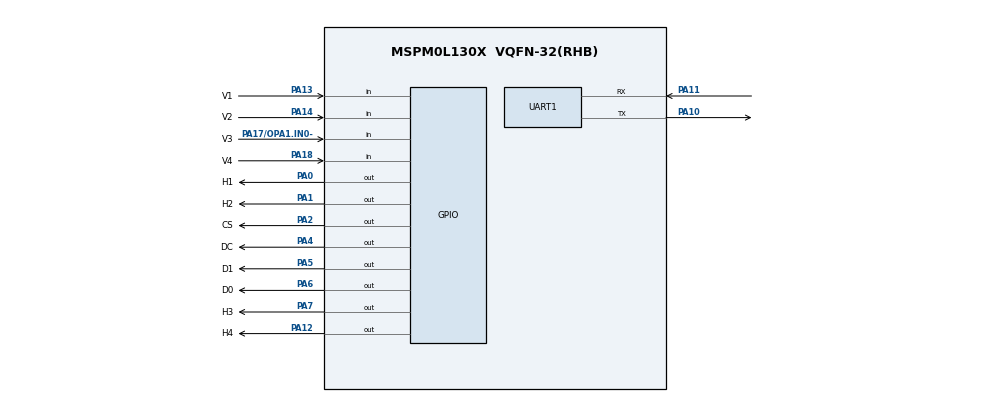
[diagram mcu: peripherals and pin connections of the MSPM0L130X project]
/**
 * @cliArgs --device "MSPM0L130X" --package "VQFN-32(RHB)" --part "Default" --product "mspm0_sdk@1.20.01.06"
 * @versions {"tool":"1.18.1+3343"}
 */

/**
 * Import the modules used in this configuration.
 */
const Board  = scripting.addModule("/ti/driverlib/Board");
const GPIO   = scripting.addModule("/ti/driverlib/GPIO", {}, false);
const GPIO1  = GPIO.addInstance();
const GPIO2  = GPIO.addInstance();
const GPIO3  = GPIO.addInstance();
const SYSCTL = scripting.addModule("/ti/driverlib/SYSCTL");
const UART   = scripting.addModule("/ti/driverlib/UART", {}, false);
const UART1  = UART.addInstance();

/**
 * Write custom configuration values to the imported modules.
 */
const gate6  = system.clockTree["MFCLKGATE"];
gate6.enable = true;

const gate7  = system.clockTree["MFPCLKGATE"];
gate7.enable = true;


GPIO1.$name                          = "GPIO_GRP_0";
GPIO1.associatedPins.create(4);
GPIO1.associatedPins[0].$name        = "CS";
GPIO1.associatedPins[0].initialValue = "SET";
GPIO1.associatedPins[0].assignedPort = "PORTA";
GPIO1.associatedPins[0].pin.$assign  = "PA2";
GPIO1.associatedPins[1].$name        = "D0";
GPIO1.associatedPins[1].pin.$assign  = "PA6";
GPIO1.associatedPins[2].$name        = "D1";
GPIO1.associatedPins[2].pin.$assign  = "PA5";
GPIO1.associatedPins[3].$name        = "DC";
GPIO1.associatedPins[3].pin.$assign  = "PA4";

GPIO2.$name                         = "H";
GPIO2.associatedPins.create(4);
GPIO2.associatedPins[0].$name       = "H1";
GPIO2.associatedPins[0].pin.$assign = "PA0";
GPIO2.associatedPins[1].$name       = "H2";
GPIO2.associatedPins[1].pin.$assign = "PA1";
GPIO2.associatedPins[2].$name       = "H3";
GPIO2.associatedPins[2].pin.$assign = "PA7";
GPIO2.associatedPins[3].$name       = "H4";
GPIO2.associatedPins[3].pin.$assign = "PA12";

GPIO3.$name                              = "V";
GPIO3.associatedPins.create(4);
GPIO3.associatedPins[0].internalResistor = "PULL_UP";
GPIO3.associatedPins[0].$name            = "V1";
GPIO3.associatedPins[0].direction        = "INPUT";
GPIO3.associatedPins[0].pin.$assign      = "PA13";
GPIO3.associatedPins[1].$name            = "V2";
GPIO3.associatedPins[1].internalResistor = "PULL_UP";
GPIO3.associatedPins[1].direction        = "INPUT";
GPIO3.associatedPins[1].pin.$assign      = "PA14";
GPIO3.associatedPins[2].$name            = "V3";
GPIO3.associatedPins[2].internalResistor = "PULL_UP";
GPIO3.associatedPins[2].direction        = "INPUT";
GPIO3.associatedPins[2].pin.$assign      = "PA17/OPA1.IN0-";
GPIO3.associatedPins[3].$name            = "V4";
GPIO3.associatedPins[3].internalResistor = "PULL_UP";
GPIO3.associatedPins[3].direction        = "INPUT";
GPIO3.associatedPins[3].pin.$assign      = "PA18";

SYSCTL.MFCLKEn     = true;
SYSCTL.MFPCLKEn    = true;
SYSCTL.clockTreeEn = true;

UART1.$name                    = "UART_0";
UART1.uartClkSrc               = "MFCLK";
UART1.targetBaudRate           = 115200;
UART1.peripheral.$assign       = "UART1";
UART1.peripheral.rxPin.$assign = "PA11";
UART1.peripheral.txPin.$assign = "PA10";
UART1.txPinConfig.$name        = "ti_driverlib_gpio_GPIOPinGeneric0";
UART1.rxPinConfig.$name        = "ti_driverlib_gpio_GPIOPinGeneric1";

/**
 * Pinmux solution for unlocked pins/peripherals. This ensures that minor changes to the automatic solver in a future
 * version of the tool will not impact the pinmux you originally saw.  These lines can be completely deleted in order to
 * re-solve from scratch.
 */
Board.peripheral.$suggestSolution          = "DEBUGSS";
Board.peripheral.swclkPin.$suggestSolution = "PA20";
Board.peripheral.swdioPin.$suggestSolution = "PA19";
